VERSION ""

NS_ :

BS_:

BU_:

BO_ 2566848608 osm_msg5: 8 Vector__XXX
 SG_ tp_alarm : 0|1@1+ (1,0) [0|1] "" Vector__XXX

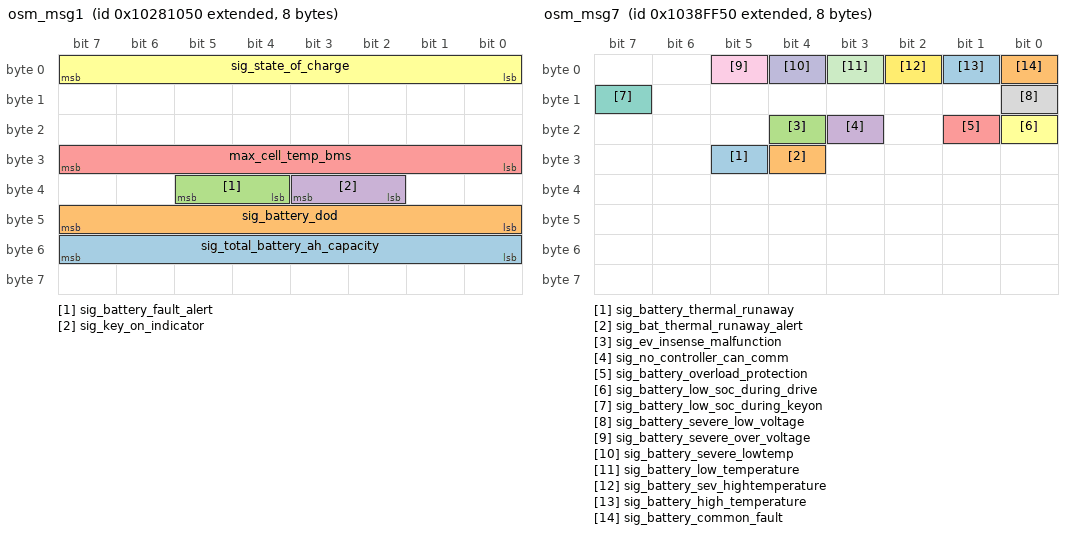
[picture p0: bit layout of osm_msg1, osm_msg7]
BO_ 2418544720 osm_msg1: 8 Vector__XXX
 SG_ sig_total_battery_ah_capacity : 48|8@1+ (1,0) [0|255] "" Vector__XXX
 SG_ sig_battery_dod : 40|8@1+ (1,0) [0|255] "" Vector__XXX
 SG_ sig_battery_fault_alert : 36|2@1+ (1,0) [0|3] "" Vector__XXX
 SG_ sig_key_on_indicator : 34|2@1+ (1,0) [0|3] "" Vector__XXX
 SG_ max_cell_temp_bms : 24|8@1- (1,0) [-128|127] "" Vector__XXX
 SG_ sig_state_of_charge : 0|8@1+ (1,0) [0|255] "" Vector__XXX

BO_ 2419654480 osm_msg7: 8 Vector__XXX
 SG_ sig_battery_thermal_runaway : 29|1@1+ (1,0) [0|1] "" Vector__XXX
 SG_ sig_bat_thermal_runaway_alert : 28|1@1+ (1,0) [0|1] "" Vector__XXX
 SG_ sig_ev_insense_malfunction : 20|1@1+ (1,0) [0|1] "" Vector__XXX
 SG_ sig_no_controller_can_comm : 19|1@1+ (1,0) [0|1] "" Vector__XXX
 SG_ sig_battery_overload_protection : 17|1@1+ (1,0) [0|1] "" Vector__XXX
 SG_ sig_battery_low_soc_during_drive : 16|1@1+ (1,0) [0|1] "" Vector__XXX
 SG_ sig_battery_low_soc_during_keyon : 15|1@1+ (1,0) [0|1] "" Vector__XXX
 SG_ sig_battery_severe_low_voltage : 8|1@1+ (1,0) [0|1] "" Vector__XXX
 SG_ sig_battery_severe_over_voltage : 5|1@1+ (1,0) [0|1] "" Vector__XXX
 SG_ sig_battery_severe_lowtemp : 4|1@1+ (1,0) [0|1] "" Vector__XXX
 SG_ sig_battery_low_temperature : 3|1@1+ (1,0) [0|1] "" Vector__XXX
 SG_ sig_battery_sev_hightemperature : 2|1@1+ (1,0) [0|1] "" Vector__XXX
 SG_ sig_battery_high_temperature : 1|1@1+ (1,0) [0|1] "" Vector__XXX
 SG_ sig_battery_common_fault : 0|1@1+ (1,0) [0|1] "" Vector__XXX

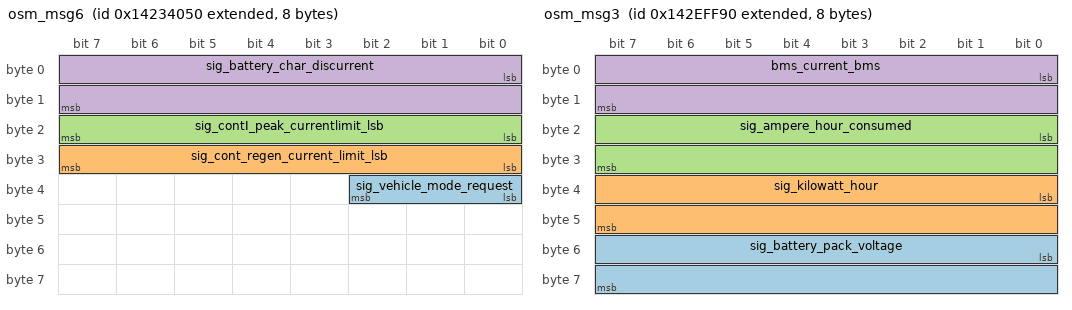
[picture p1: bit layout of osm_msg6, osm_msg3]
BO_ 2485338192 osm_msg6: 8 Vector__XXX
 SG_ sig_vehicle_mode_request : 32|3@1+ (1,0) [0|7] "" Vector__XXX
 SG_ sig_cont_regen_current_limit_lsb : 24|8@1+ (1,0) [0|255] "" Vector__XXX
 SG_ sig_contI_peak_currentlimit_lsb : 16|8@1+ (1,0) [0|255] "" Vector__XXX
 SG_ sig_battery_char_discurrent : 0|16@1- (0.1,0.0) [-3276.8|3276.7000000000003] "" Vector__XXX

BO_ 2485403728 osm_msg8: 8 Vector__XXX
 SG_ max_cell_voltage_bms : 32|16@1+ (0.001,0.0) [0.0|65.535] "" Vector__XXX
 SG_ min_cell_voltage_bms : 0|16@1+ (0.001,0.0) [0.0|65.535] "" Vector__XXX

BO_ 2486108048 osm_msg3: 8 Vector__XXX
 SG_ sig_battery_pack_voltage : 48|16@1+ (0.01,0.0) [0.0|655.35] "" Vector__XXX
 SG_ sig_kilowatt_hour : 32|16@1- (0.01,0.0) [-327.68|327.67] "" Vector__XXX
 SG_ sig_ampere_hour_consumed : 16|16@1- (0.01,0.0) [-327.68|327.67] "" Vector__XXX
 SG_ bms_current_bms : 0|16@1- (0.1,0.0) [-3276.8|3276.7000000000003] "" Vector__XXX

BO_ 2566849376 osm_msg4: 8 Vector__XXX
 SG_ sig_battery_state : 56|8@1+ (1,0) [0|255] "" Vector__XXX
 SG_ sig_battery_charging_cycles : 40|16@1+ (1,0) [0|65535] "" Vector__XXX

BO_ 2418499664 osm_msg9: 8 Vector__XXX
 SG_ sig_bms_software_ver : 32|32@1+ (1,0) [0|4294967295] "" Vector__XXX
 SG_ sig_bms_hardware_ver : 0|32@1+ (1,0) [0|4294967295] "" Vector__XXX

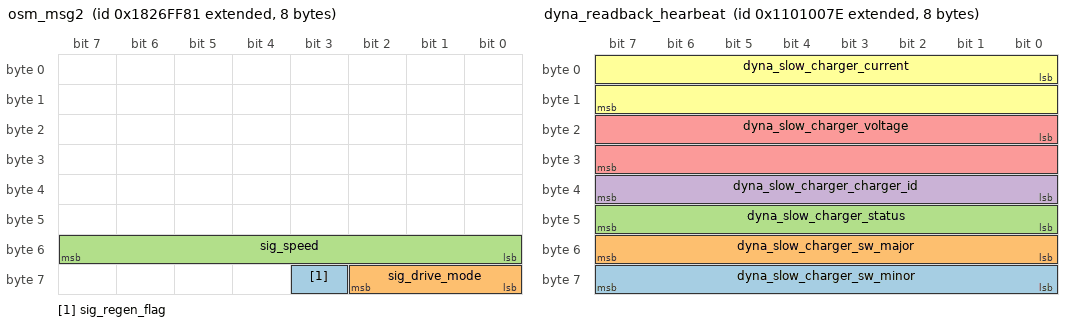
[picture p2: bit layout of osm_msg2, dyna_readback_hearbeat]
BO_ 2552692609 osm_msg2: 8 Vector__XXX
 SG_ sig_regen_flag : 59|1@1+ (1,0) [0|1] "" Vector__XXX
 SG_ sig_drive_mode : 56|3@1+ (1,0) [0|7] "" Vector__XXX
 SG_ sig_speed : 48|8@1+ (1,0) [0|255] "" Vector__XXX

BO_ 2432761982 dyna_readback_hearbeat: 8 Vector__XXX
 SG_ dyna_slow_charger_sw_minor : 56|8@1+ (1,0) [0|255] "" Vector__XXX
 SG_ dyna_slow_charger_sw_major : 48|8@1+ (1,0) [0|255] "" Vector__XXX
 SG_ dyna_slow_charger_status : 40|8@1+ (1,0) [0|255] "" Vector__XXX
 SG_ dyna_slow_charger_charger_id : 32|8@1+ (1,0) [0|255] "" Vector__XXX
 SG_ dyna_slow_charger_voltage : 16|16@1+ (1,0) [0|65535] "" Vector__XXX
 SG_ dyna_slow_charger_current : 0|16@1+ (1,0) [0|65535] "" Vector__XXX

BO_ 2424406782 stecom_charger_mode_set: 8 Vector__XXX
 SG_ dyna_out_accept_2 : 8|8@1+ (1,0) [0|255] "" Vector__XXX
 SG_ dyna_out_accept : 0|8@1+ (1,0) [0|255] "" Vector__XXX

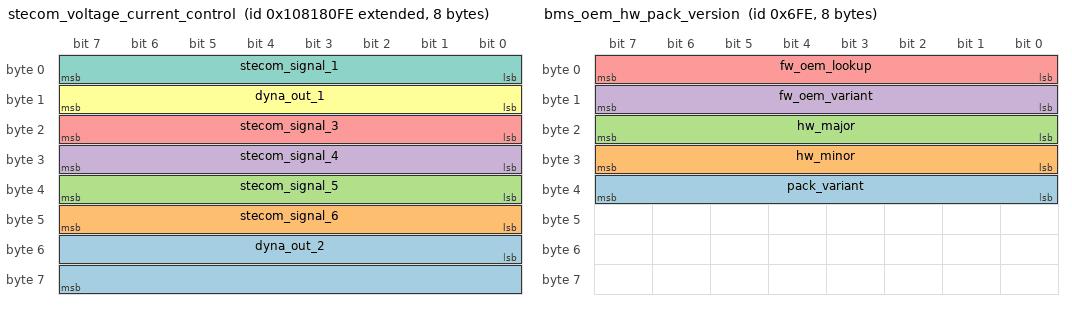
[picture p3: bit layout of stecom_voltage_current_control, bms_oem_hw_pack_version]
BO_ 2424406270 stecom_voltage_current_control: 8 Vector__XXX
 SG_ dyna_out_2 : 48|16@1+ (1,0) [0|65535] "" Vector__XXX
 SG_ stecom_signal_6 : 40|8@1+ (1,0) [0|255] "" Vector__XXX
 SG_ stecom_signal_5 : 32|8@1+ (1,0) [0|255] "" Vector__XXX
 SG_ stecom_signal_4 : 24|8@1+ (1,0) [0|255] "" Vector__XXX
 SG_ stecom_signal_3 : 16|8@1+ (1,0) [0|255] "" Vector__XXX
 SG_ dyna_out_1 : 8|8@1+ (1,0) [0|255] "" Vector__XXX
 SG_ stecom_signal_1 : 0|8@1+ (1,0) [0|255] "" Vector__XXX

BO_ 1790 bms_oem_hw_pack_version: 8 Vector__XXX
 SG_ pack_variant : 32|8@1+ (1,0) [0|255] "" Vector__XXX
 SG_ hw_minor : 24|8@1+ (1,0) [0|255] "" Vector__XXX
 SG_ hw_major : 16|8@1+ (1,0) [0|255] "" Vector__XXX
 SG_ fw_oem_variant : 8|8@1+ (1,0) [0|255] "" Vector__XXX
 SG_ fw_oem_lookup : 0|8@1+ (1,0) [0|255] "" Vector__XXX

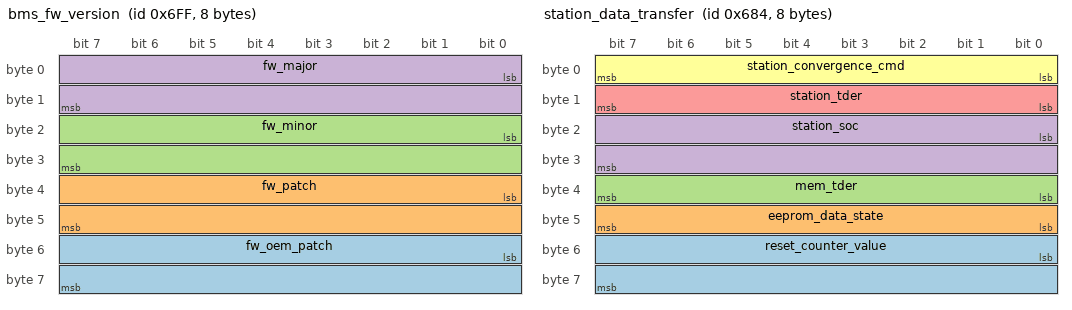
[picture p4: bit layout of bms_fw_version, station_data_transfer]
BO_ 1791 bms_fw_version: 8 Vector__XXX
 SG_ fw_oem_patch : 48|16@1+ (1,0) [0|65535] "" Vector__XXX
 SG_ fw_patch : 32|16@1+ (1,0) [0|65535] "" Vector__XXX
 SG_ fw_minor : 16|16@1+ (1,0) [0|65535] "" Vector__XXX
 SG_ fw_major : 0|16@1+ (1,0) [0|65535] "" Vector__XXX

BO_ 1668 station_data_transfer: 8 Vector__XXX
 SG_ reset_counter_value : 48|16@1+ (1,0) [0|65535] "" Vector__XXX
 SG_ eeprom_data_state : 40|8@1+ (1,0) [0|255] "" Vector__XXX
 SG_ mem_tder : 32|8@1+ (1,0) [0|255] "" Vector__XXX
 SG_ station_soc : 16|16@1+ (1,0.1) [0.1|65535.1] "" Vector__XXX
 SG_ station_tder : 8|8@1+ (1,0) [0|255] "" Vector__XXX
 SG_ station_convergence_cmd : 0|8@1+ (1,0) [0|255] "" Vector__XXX

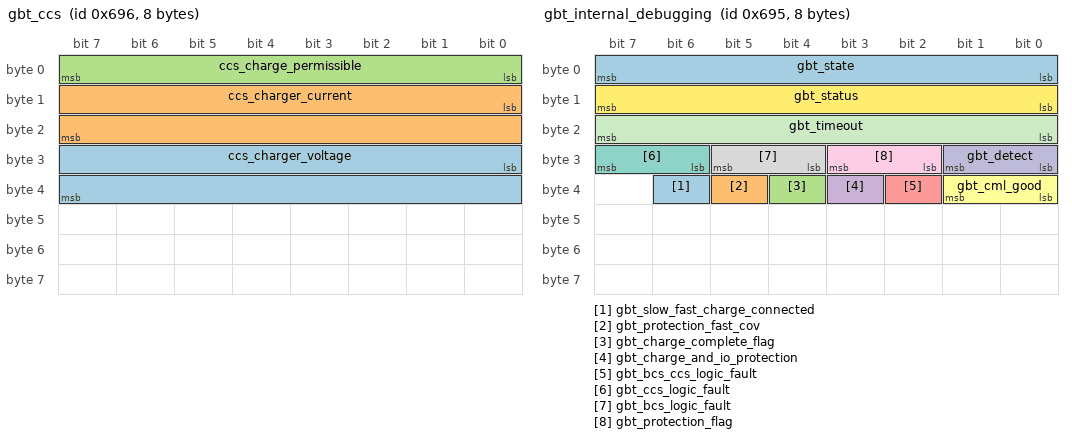
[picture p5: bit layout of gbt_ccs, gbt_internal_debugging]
BO_ 1686 gbt_ccs: 8 Vector__XXX
 SG_ ccs_charger_voltage : 24|16@1+ (0.1,0.0) [0.0|6553.5] "" Vector__XXX
 SG_ ccs_charger_current : 8|16@1- (0.1,-400.0) [-3676.8|2876.7000000000003] "" Vector__XXX
 SG_ ccs_charge_permissible : 0|8@1+ (1,0) [0|255] "" Vector__XXX

BO_ 1681 gbt_bst_cst: 8 Vector__XXX
 SG_ cst_byte3 : 56|8@1+ (1,0) [0|255] "" Vector__XXX
 SG_ cst_byte2 : 48|8@1+ (1,0) [0|255] "" Vector__XXX
 SG_ csr_byte1 : 40|8@1+ (1,0) [0|255] "" Vector__XXX
 SG_ cst_byte0 : 32|8@1+ (1,0) [0|255] "" Vector__XXX
 SG_ bst_voltage_error : 26|2@1+ (1,0) [0|3] "" Vector__XXX
 SG_ bst_current_error : 24|2@1+ (1,0) [0|3] "" Vector__XXX
 SG_ bst_other_fault : 22|2@1+ (1,0) [0|3] "" Vector__XXX
 SG_ bst_voltage_detection_fault : 20|2@1+ (1,0) [0|3] "" Vector__XXX
 SG_ bst_hv_relay_fault : 18|2@1+ (1,0) [0|3] "" Vector__XXX
 SG_ bst_battery_ot_fault : 16|2@1+ (1,0) [0|3] "" Vector__XXX
 SG_ bst_charging_connector_fault : 14|2@1+ (1,0) [0|3] "" Vector__XXX
 SG_ bst_bms_component_fault : 12|2@1+ (1,0) [0|3] "" Vector__XXX
 SG_ bst_output_connector_ot_fault : 10|2@1+ (1,0) [0|3] "" Vector__XXX
 SG_ bst_insulation_fault : 8|2@1+ (1,0) [0|3] "" Vector__XXX
 SG_ bst_cst_cause : 6|2@1+ (1,0) [0|3] "" Vector__XXX
 SG_ bst_max_cell_volt_cause : 4|2@1+ (1,0) [0|3] "" Vector__XXX
 SG_ bst_pack_voltage_cause : 2|2@1+ (1,0) [0|3] "" Vector__XXX
 SG_ bst_soc_cause : 0|2@1+ (1,0) [0|3] "" Vector__XXX

BO_ 1685 gbt_internal_debugging: 8 Vector__XXX
 SG_ gbt_slow_fast_charge_connected : 38|1@1+ (1,0) [0|1] "" Vector__XXX
 SG_ gbt_protection_fast_cov : 37|1@1+ (1,0) [0|1] "" Vector__XXX
 SG_ gbt_charge_complete_flag : 36|1@1+ (1,0) [0|1] "" Vector__XXX
 SG_ gbt_charge_and_io_protection : 35|1@1+ (1,0) [0|1] "" Vector__XXX
 SG_ gbt_bcs_ccs_logic_fault : 34|1@1+ (1,0) [0|1] "" Vector__XXX
 SG_ gbt_cml_good : 32|2@1+ (1,0) [0|3] "" Vector__XXX
 SG_ gbt_ccs_logic_fault : 30|2@1+ (1,0) [0|3] "" Vector__XXX
 SG_ gbt_bcs_logic_fault : 28|2@1+ (1,0) [0|3] "" Vector__XXX
 SG_ gbt_protection_flag : 26|2@1+ (1,0) [0|3] "" Vector__XXX
 SG_ gbt_detect : 24|2@1+ (1,0) [0|3] "" Vector__XXX
 SG_ gbt_timeout : 16|8@1+ (1,0) [0|255] "" Vector__XXX
 SG_ gbt_status : 8|8@1+ (1,0) [0|255] "" Vector__XXX
 SG_ gbt_state : 0|8@1+ (1,0) [0|255] "" Vector__XXX

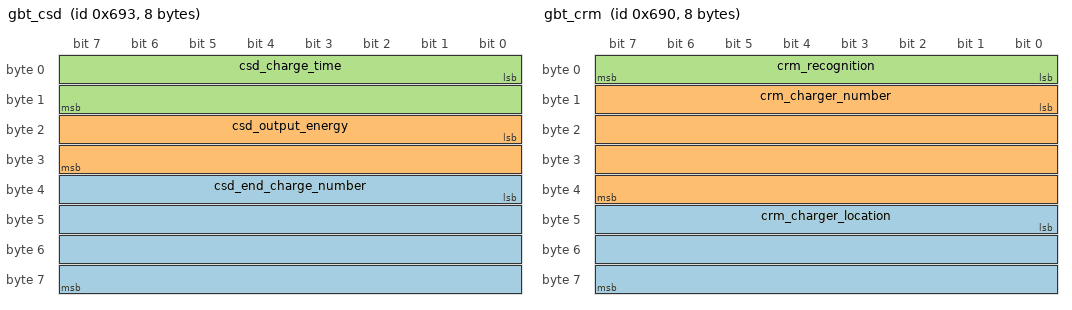
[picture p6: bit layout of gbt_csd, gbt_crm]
BO_ 1683 gbt_csd: 8 Vector__XXX
 SG_ csd_end_charge_number : 32|32@1+ (1,0) [0|4294967295] "" Vector__XXX
 SG_ csd_output_energy : 16|16@1+ (0.1,0.0) [0.0|6553.5] "" Vector__XXX
 SG_ csd_charge_time : 0|16@1+ (1,0) [0|65535] "" Vector__XXX

BO_ 1680 gbt_crm: 8 Vector__XXX
 SG_ crm_charger_location : 40|24@1+ (1,0) [0|16777215] "" Vector__XXX
 SG_ crm_charger_number : 8|32@1+ (1,0) [0|4294967295] "" Vector__XXX
 SG_ crm_recognition : 0|8@1+ (1,0) [0|255] "" Vector__XXX

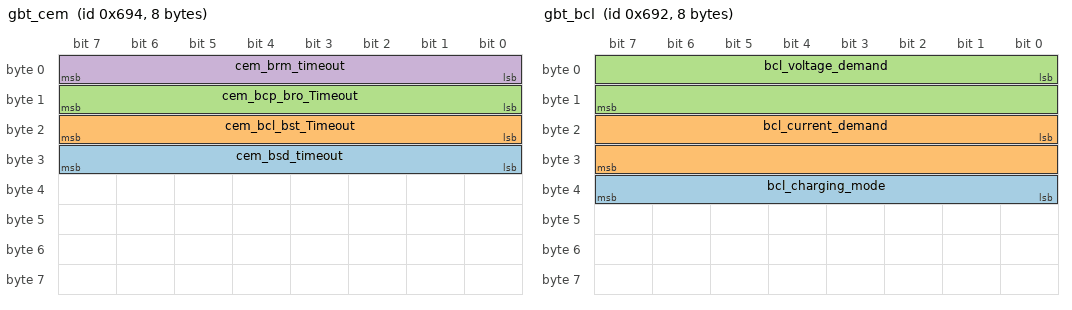
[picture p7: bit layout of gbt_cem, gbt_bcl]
BO_ 1684 gbt_cem: 8 Vector__XXX
 SG_ cem_bsd_timeout : 24|8@1+ (1,0) [0|255] "" Vector__XXX
 SG_ cem_bcl_bst_Timeout : 16|8@1+ (1,0) [0|255] "" Vector__XXX
 SG_ cem_bcp_bro_Timeout : 8|8@1+ (1,0) [0|255] "" Vector__XXX
 SG_ cem_brm_timeout : 0|8@1+ (1,0) [0|255] "" Vector__XXX

BO_ 1682 gbt_bcl: 8 Vector__XXX
 SG_ bcl_charging_mode : 32|8@1+ (1,0) [0|255] "" Vector__XXX
 SG_ bcl_current_demand : 16|16@1+ (0.1,-40.0) [-40.0|6513.5] "" Vector__XXX
 SG_ bcl_voltage_demand : 0|16@1+ (0.1,0.0) [0.0|6553.5] "" Vector__XXX

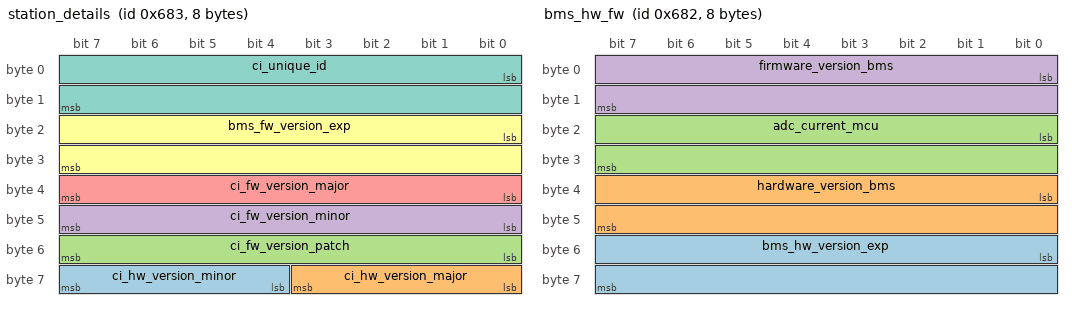
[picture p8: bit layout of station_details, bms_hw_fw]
BO_ 1667 station_details: 8 Vector__XXX
 SG_ ci_hw_version_minor : 60|4@1+ (1,0) [0|15] "" Vector__XXX
 SG_ ci_hw_version_major : 56|4@1+ (1,0) [0|15] "" Vector__XXX
 SG_ ci_fw_version_patch : 48|8@1+ (1,0) [0|255] "" Vector__XXX
 SG_ ci_fw_version_minor : 40|8@1+ (1,0) [0|255] "" Vector__XXX
 SG_ ci_fw_version_major : 32|8@1+ (1,0) [0|255] "" Vector__XXX
 SG_ bms_fw_version_exp : 16|16@1+ (1,0) [0|65535] "" Vector__XXX
 SG_ ci_unique_id : 0|16@1+ (1,0) [0|65535] "" Vector__XXX

BO_ 1666 bms_hw_fw: 8 Vector__XXX
 SG_ bms_hw_version_exp : 48|16@1+ (1,0) [0|65535] "" Vector__XXX
 SG_ hardware_version_bms : 32|16@1+ (1,0) [0|65535] "" Vector__XXX
 SG_ adc_current_mcu : 16|16@1+ (1,0) [0|65535] "" Vector__XXX
 SG_ firmware_version_bms : 0|16@1+ (1,0) [0|65535] "" Vector__XXX

BO_ 1665 bms_unique_Key: 8 Vector__XXX
 SG_ bms_unique_key : 0|64@1+ (1,0) [0|18446744073709551615] "" Vector__XXX

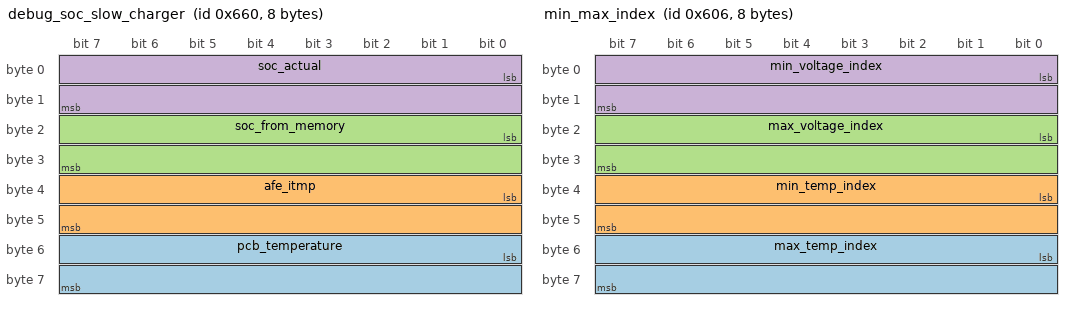
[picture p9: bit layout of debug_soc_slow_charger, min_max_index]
BO_ 1632 debug_soc_slow_charger: 8 Vector__XXX
 SG_ pcb_temperature : 48|16@1+ (0.01,-100.0) [-100.0|555.35] "" Vector__XXX
 SG_ afe_itmp : 32|16@1+ (0.01,-100.0) [-100.0|555.35] "" Vector__XXX
 SG_ soc_from_memory : 16|16@1+ (1,0) [0|65535] "" Vector__XXX
 SG_ soc_actual : 0|16@1+ (0.01,0.0) [0.0|655.35] "" Vector__XXX

BO_ 1542 min_max_index: 8 Vector__XXX
 SG_ max_temp_index : 48|16@1+ (1,0) [0|65535] "" Vector__XXX
 SG_ min_temp_index : 32|16@1+ (1,0) [0|65535] "" Vector__XXX
 SG_ max_voltage_index : 16|16@1+ (1,0) [0|65535] "" Vector__XXX
 SG_ min_voltage_index : 0|16@1+ (1,0) [0|65535] "" Vector__XXX

BO_ 1543 history_of_protections: 8 Vector__XXX
 SG_ reset_cause : 48|16@1+ (1,0) [0|65535] "" Vector__XXX
 SG_ characterization_cycle_count : 32|16@1+ (0.1,0.0) [0.0|6553.5] "" Vector__XXX
 SG_ ib1_bms_hist : 20|1@1+ (1,0) [0|1] "" Vector__XXX
 SG_ ccov_bms_hist : 19|1@1+ (1,0) [0|1] "" Vector__XXX
 SG_ sc_coc1_bms_hist : 18|1@1+ (1,0) [0|1] "" Vector__XXX
 SG_ ccuv_bms_hist : 17|1@1+ (1,0) [0|1] "" Vector__XXX
 SG_ icp_hist : 16|1@1+ (1,0) [0|1] "" Vector__XXX
 SG_ sc_coc_bms_hist : 15|1@1+ (1,0) [0|1] "" Vector__XXX
 SG_ roc_bms_hist : 14|1@1+ (1,0) [0|1] "" Vector__XXX
 SG_ scf_bms_hist : 13|1@1+ (1,0) [0|1] "" Vector__XXX
 SG_ tso_bms_hist : 12|1@1+ (1,0) [0|1] "" Vector__XXX
 SG_ ib_bms_hist : 11|1@1+ (1,0) [0|1] "" Vector__XXX
 SG_ cso_bms_hist : 10|1@1+ (1,0) [0|1] "" Vector__XXX
 SG_ dut_bms_hist : 9|1@1+ (1,0) [0|1] "" Vector__XXX
 SG_ cut_bms_hist : 8|1@1+ (1,0) [0|1] "" Vector__XXX
 SG_ dot_bms_hist : 7|1@1+ (1,0) [0|1] "" Vector__XXX
 SG_ cot_bms_hist : 6|1@1+ (1,0) [0|1] "" Vector__XXX
 SG_ doc_bms_hist : 5|1@1+ (1,0) [0|1] "" Vector__XXX
 SG_ coc_bms_hist : 4|1@1+ (1,0) [0|1] "" Vector__XXX
 SG_ puv_bms_hist : 3|1@1+ (1,0) [0|1] "" Vector__XXX
 SG_ pov_bms_hist : 2|1@1+ (1,0) [0|1] "" Vector__XXX
 SG_ cuv_bms_hist : 1|1@1+ (1,0) [0|1] "" Vector__XXX
 SG_ cov_bms_hist : 0|1@1+ (1,0) [0|1] "" Vector__XXX

BO_ 1664 battery_unique_key: 8 Vector__XXX
 SG_ battery_unique_key : 0|64@1+ (1,0) [0|18446744073709551615] "" Vector__XXX

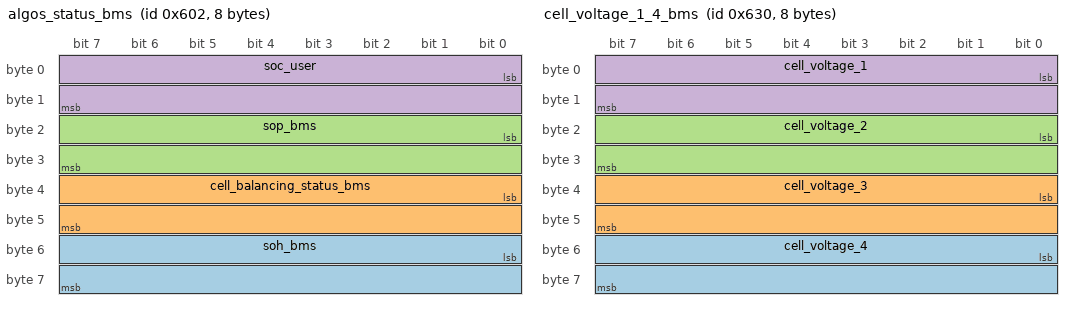
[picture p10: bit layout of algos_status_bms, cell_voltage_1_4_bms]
BO_ 1538 algos_status_bms: 8 Vector__XXX
 SG_ soh_bms : 48|16@1+ (0.01,0.0) [0.0|655.35] "" Vector__XXX
 SG_ cell_balancing_status_bms : 32|16@1+ (1,0) [0|65535] "" Vector__XXX
 SG_ sop_bms : 16|16@1+ (1,0) [0|65535] "" Vector__XXX
 SG_ soc_user : 0|16@1+ (0.01,0.0) [0.0|655.35] "" Vector__XXX

BO_ 1537 safety_status_bms: 8 Vector__XXX
 SG_ ib1_bms_flag : 52|1@1+ (1,0) [0|1] "" Vector__XXX
 SG_ ccov_flag_bms : 51|1@1+ (1,0) [0|1] "" Vector__XXX
 SG_ sc_coc1_flag_bms : 50|1@1+ (1,0) [0|1] "" Vector__XXX
 SG_ ccuv_flag_bms : 49|1@1+ (1,0) [0|1] "" Vector__XXX
 SG_ icp_flag : 48|1@1+ (1,0) [0|1] "" Vector__XXX
 SG_ sc_coc_flag_bms : 47|1@1+ (1,0) [0|1] "" Vector__XXX
 SG_ roc_flag_bms : 46|1@1+ (1,0) [0|1] "" Vector__XXX
 SG_ scf_flag_bms : 45|1@1+ (1,0) [0|1] "" Vector__XXX
 SG_ tso_flag_bms : 44|1@1+ (1,0) [0|1] "" Vector__XXX
 SG_ ib_bms_flag : 43|1@1+ (1,0) [0|1] "" Vector__XXX
 SG_ cso_flag_bms : 42|1@1+ (1,0) [0|1] "" Vector__XXX
 SG_ dut_flag_bms : 41|1@1+ (1,0) [0|1] "" Vector__XXX
 SG_ cut_flag_bms : 40|1@1+ (1,0) [0|1] "" Vector__XXX
 SG_ dot_flag_bms : 39|1@1+ (1,0) [0|1] "" Vector__XXX
 SG_ cot_flag_bms : 38|1@1+ (1,0) [0|1] "" Vector__XXX
 SG_ doc_flag_bms : 37|1@1+ (1,0) [0|1] "" Vector__XXX
 SG_ coc_flag_bms : 36|1@1+ (1,0) [0|1] "" Vector__XXX
 SG_ puv_flag_bms : 35|1@1+ (1,0) [0|1] "" Vector__XXX
 SG_ pov_flag_bms : 34|1@1+ (1,0) [0|1] "" Vector__XXX
 SG_ cuv_flag_bms : 33|1@1+ (1,0) [0|1] "" Vector__XXX
 SG_ cov_flag_bms : 32|1@1+ (1,0) [0|1] "" Vector__XXX
 SG_ ib1_bms : 20|1@1+ (1,0) [0|1] "" Vector__XXX
 SG_ ccov_bms : 19|1@1+ (1,0) [0|1] "" Vector__XXX
 SG_ sc_coc1_bms : 18|1@1+ (1,0) [0|1] "" Vector__XXX
 SG_ ccuv_bms : 17|1@1+ (1,0) [0|1] "" Vector__XXX
 SG_ icp_status : 16|1@1+ (1,0) [0|1] "" Vector__XXX
 SG_ sc_coc_bms : 15|1@1+ (1,0) [0|1] "" Vector__XXX
 SG_ roc_bms : 14|1@1+ (1,0) [0|1] "" Vector__XXX
 SG_ scf_bms : 13|1@1+ (1,0) [0|1] "" Vector__XXX
 SG_ tso_bms : 12|1@1+ (1,0) [0|1] "" Vector__XXX
 SG_ ib_bms : 11|1@1+ (1,0) [0|1] "" Vector__XXX
 SG_ cso_bms : 10|1@1+ (1,0) [0|1] "" Vector__XXX
 SG_ dut_bms : 9|1@1+ (1,0) [0|1] "" Vector__XXX
 SG_ cut_bms : 8|1@1+ (1,0) [0|1] "" Vector__XXX
 SG_ dot_bms : 7|1@1+ (1,0) [0|1] "" Vector__XXX
 SG_ cot_bms : 6|1@1+ (1,0) [0|1] "" Vector__XXX
 SG_ doc_bms : 5|1@1+ (1,0) [0|1] "" Vector__XXX
 SG_ coc_bms : 4|1@1+ (1,0) [0|1] "" Vector__XXX
 SG_ puv_bms : 3|1@1+ (1,0) [0|1] "" Vector__XXX
 SG_ pov_bms : 2|1@1+ (1,0) [0|1] "" Vector__XXX
 SG_ cuv_bms : 1|1@1+ (1,0) [0|1] "" Vector__XXX
 SG_ cov_bms : 0|1@1+ (1,0) [0|1] "" Vector__XXX

BO_ 1584 cell_voltage_1_4_bms: 8 Vector__XXX
 SG_ cell_voltage_4 : 48|16@1+ (0.0001,0.0) [0.0|6.5535000000000005] "" Vector__XXX
 SG_ cell_voltage_3 : 32|16@1+ (0.0001,0.0) [0.0|6.5535000000000005] "" Vector__XXX
 SG_ cell_voltage_2 : 16|16@1+ (0.0001,0.0) [0.0|6.5535000000000005] "" Vector__XXX
 SG_ cell_voltage_1 : 0|16@1+ (0.0001,0.0) [0.0|6.5535000000000005] "" Vector__XXX

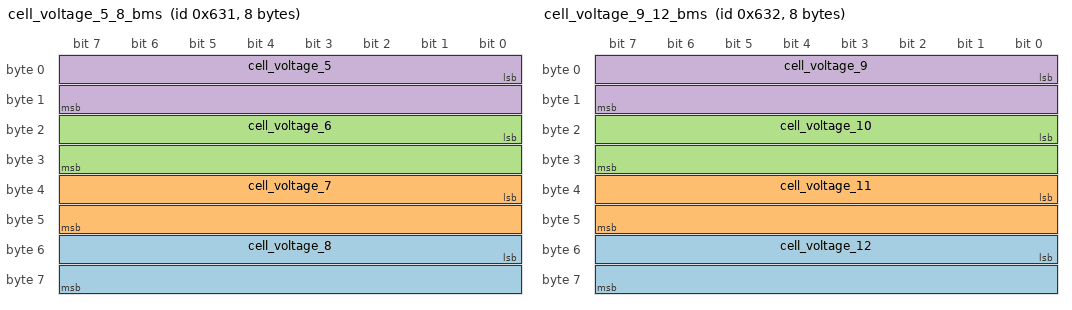
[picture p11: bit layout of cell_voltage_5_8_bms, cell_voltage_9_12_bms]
BO_ 1585 cell_voltage_5_8_bms: 8 Vector__XXX
 SG_ cell_voltage_8 : 48|16@1+ (0.0001,0.0) [0.0|6.5535000000000005] "" Vector__XXX
 SG_ cell_voltage_7 : 32|16@1+ (0.0001,0.0) [0.0|6.5535000000000005] "" Vector__XXX
 SG_ cell_voltage_6 : 16|16@1+ (0.0001,0.0) [0.0|6.5535000000000005] "" Vector__XXX
 SG_ cell_voltage_5 : 0|16@1+ (0.0001,0.0) [0.0|6.5535000000000005] "" Vector__XXX

BO_ 1586 cell_voltage_9_12_bms: 8 Vector__XXX
 SG_ cell_voltage_12 : 48|16@1+ (0.0001,0.0) [0.0|6.5535000000000005] "" Vector__XXX
 SG_ cell_voltage_11 : 32|16@1+ (0.0001,0.0) [0.0|6.5535000000000005] "" Vector__XXX
 SG_ cell_voltage_10 : 16|16@1+ (0.0001,0.0) [0.0|6.5535000000000005] "" Vector__XXX
 SG_ cell_voltage_9 : 0|16@1+ (0.0001,0.0) [0.0|6.5535000000000005] "" Vector__XXX

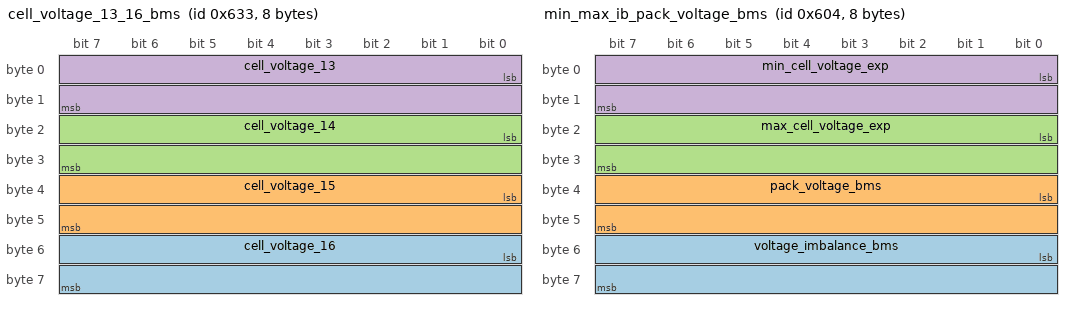
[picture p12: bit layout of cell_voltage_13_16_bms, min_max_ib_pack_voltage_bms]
BO_ 1587 cell_voltage_13_16_bms: 8 Vector__XXX
 SG_ cell_voltage_16 : 48|16@1+ (0.0001,0.0) [0.0|6.5535000000000005] "" Vector__XXX
 SG_ cell_voltage_15 : 32|16@1+ (0.0001,0.0) [0.0|6.5535000000000005] "" Vector__XXX
 SG_ cell_voltage_14 : 16|16@1+ (0.0001,0.0) [0.0|6.5535000000000005] "" Vector__XXX
 SG_ cell_voltage_13 : 0|16@1+ (0.0001,0.0) [0.0|6.5535000000000005] "" Vector__XXX

BO_ 1540 min_max_ib_pack_voltage_bms: 8 Vector__XXX
 SG_ voltage_imbalance_bms : 48|16@1+ (0.0001,0.0) [0.0|6.5535000000000005] "" Vector__XXX
 SG_ pack_voltage_bms : 32|16@1+ (0.01,0.0) [0.0|655.35] "" Vector__XXX
 SG_ max_cell_voltage_exp : 16|16@1+ (0.0001,0.0) [0.0|6.5535000000000005] "" Vector__XXX
 SG_ min_cell_voltage_exp : 0|16@1+ (0.0001,0.0) [0.0|6.5535000000000005] "" Vector__XXX

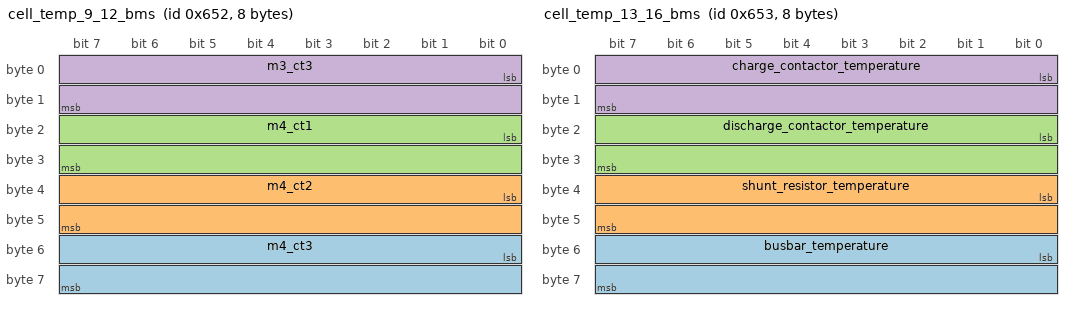
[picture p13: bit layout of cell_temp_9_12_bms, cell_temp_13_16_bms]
BO_ 1618 cell_temp_9_12_bms: 8 Vector__XXX
 SG_ m4_ct3 : 48|16@1+ (0.01,-100.0) [-100.0|555.35] "" Vector__XXX
 SG_ m4_ct2 : 32|16@1+ (0.01,-100.0) [-100.0|555.35] "" Vector__XXX
 SG_ m4_ct1 : 16|16@1+ (0.01,-100.0) [-100.0|555.35] "" Vector__XXX
 SG_ m3_ct3 : 0|16@1+ (0.01,-100.0) [-100.0|555.35] "" Vector__XXX

BO_ 1619 cell_temp_13_16_bms: 8 Vector__XXX
 SG_ busbar_temperature : 48|16@1+ (0.01,-100.0) [-100.0|555.35] "" Vector__XXX
 SG_ shunt_resistor_temperature : 32|16@1+ (0.01,-100.0) [-100.0|555.35] "" Vector__XXX
 SG_ discharge_contactor_temperature : 16|16@1+ (0.01,-100.0) [-100.0|555.35] "" Vector__XXX
 SG_ charge_contactor_temperature : 0|16@1+ (0.01,-100.0) [-100.0|555.35] "" Vector__XXX

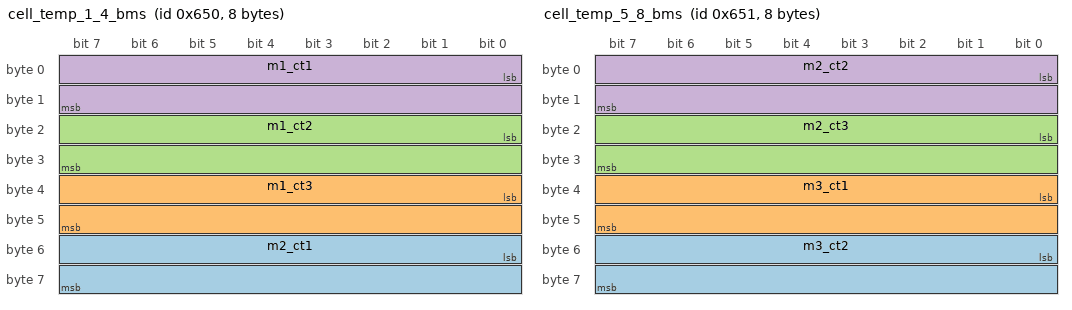
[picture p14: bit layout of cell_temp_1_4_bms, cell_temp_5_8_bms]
BO_ 1616 cell_temp_1_4_bms: 8 Vector__XXX
 SG_ m2_ct1 : 48|16@1+ (0.01,-100.0) [-100.0|555.35] "" Vector__XXX
 SG_ m1_ct3 : 32|16@1+ (0.01,-100.0) [-100.0|555.35] "" Vector__XXX
 SG_ m1_ct2 : 16|16@1+ (0.01,-100.0) [-100.0|555.35] "" Vector__XXX
 SG_ m1_ct1 : 0|16@1+ (0.01,-100.0) [-100.0|555.35] "" Vector__XXX

BO_ 1617 cell_temp_5_8_bms: 8 Vector__XXX
 SG_ m3_ct2 : 48|16@1+ (0.01,-100.0) [-100.0|555.35] "" Vector__XXX
 SG_ m3_ct1 : 32|16@1+ (0.01,-100.0) [-100.0|555.35] "" Vector__XXX
 SG_ m2_ct3 : 16|16@1+ (0.01,-100.0) [-100.0|555.35] "" Vector__XXX
 SG_ m2_ct2 : 0|16@1+ (0.01,-100.0) [-100.0|555.35] "" Vector__XXX

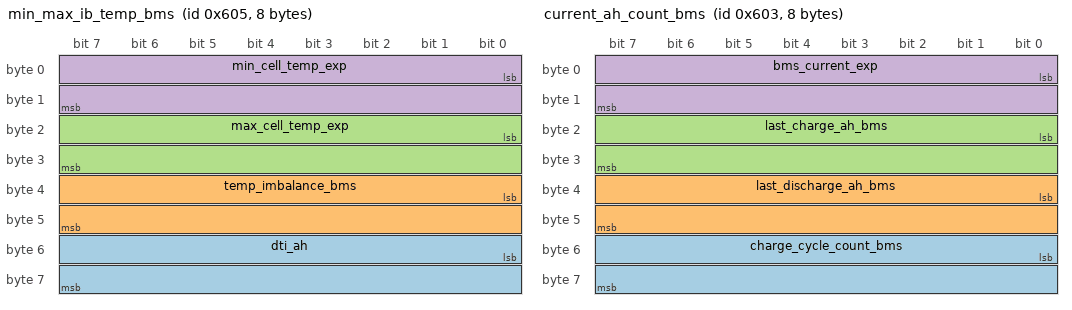
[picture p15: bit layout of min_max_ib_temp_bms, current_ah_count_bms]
BO_ 1541 min_max_ib_temp_bms: 8 Vector__XXX
 SG_ dti_ah : 48|16@1+ (0.1,0.0) [0.0|6553.5] "" Vector__XXX
 SG_ temp_imbalance_bms : 32|16@1+ (0.01,-100.0) [-100.0|555.35] "" Vector__XXX
 SG_ max_cell_temp_exp : 16|16@1+ (0.01,-100.0) [-100.0|555.35] "" Vector__XXX
 SG_ min_cell_temp_exp : 0|16@1+ (0.01,-100.0) [-100.0|555.35] "" Vector__XXX

BO_ 1539 current_ah_count_bms: 8 Vector__XXX
 SG_ charge_cycle_count_bms : 48|16@1+ (0.1,0.0) [0.0|6553.5] "" Vector__XXX
 SG_ last_discharge_ah_bms : 32|16@1+ (0.1,0.0) [0.0|6553.5] "" Vector__XXX
 SG_ last_charge_ah_bms : 16|16@1+ (0.1,0.0) [0.0|6553.5] "" Vector__XXX
 SG_ bms_current_exp : 0|16@1+ (0.1,-600.0) [-600.0|5953.5] "" Vector__XXX

BO_ 1536 sateflow_status_bms: 8 Vector__XXX
 SG_ gun_unlock_retry_count : 60|4@1+ (1,0) [0|15] "" Vector__XXX
 SG_ gun_lock_retry_count : 56|4@1+ (1,0) [0|15] "" Vector__XXX
 SG_ solenoid_feedback : 53|1@1+ (1,0) [0|1] "" Vector__XXX
 SG_ gun_lock_req : 52|1@1+ (1,0) [0|1] "" Vector__XXX
 SG_ gun_unlock_failed : 51|1@1+ (1,0) [0|1] "" Vector__XXX
 SG_ gun_unlock_status : 50|1@1+ (1,0) [0|1] "" Vector__XXX
 SG_ gun_lock_failed : 49|1@1+ (1,0) [0|1] "" Vector__XXX
 SG_ gun_lock_status : 48|1@1+ (1,0) [0|1] "" Vector__XXX
 SG_ cc_on_req : 39|1@1+ (1,0) [0|1] "" Vector__XXX
 SG_ motor_enable_out_bms : 38|1@1+ (1,0) [0|1] "" Vector__XXX
 SG_ discharge_contactor_out_bms : 37|1@1+ (1,0) [0|1] "" Vector__XXX
 SG_ discharge_precharge_out_bms : 36|1@1+ (1,0) [0|1] "" Vector__XXX
 SG_ charge_contactor_out_bms : 35|1@1+ (1,0) [0|1] "" Vector__XXX
 SG_ charge_precharge_out_bms : 34|1@1+ (1,0) [0|1] "" Vector__XXX
 SG_ proximity_pilot_in_bms : 33|1@1+ (1,0) [0|1] "" Vector__XXX
 SG_ key_in_bms : 32|1@1+ (1,0) [0|1] "" Vector__XXX
 SG_ shutdown_flag_3 : 26|1@1+ (1,0) [0|1] "" Vector__XXX
 SG_ shutdown_flag_2 : 25|1@1+ (1,0) [0|1] "" Vector__XXX
 SG_ shutdown_flag_1 : 24|1@1+ (1,0) [0|1] "" Vector__XXX
 SG_ battery_state_bms : 16|8@1+ (1,0) [0|255] "" Vector__XXX
 SG_ tp_warning : 13|1@1+ (1,0) [0|1] "" Vector__XXX
 SG_ dot_warning : 12|1@1+ (1,0) [0|1] "" Vector__XXX
 SG_ tp_alarm_exp : 11|1@1+ (1,0) [0|1] "" Vector__XXX
 SG_ charge_complete_status : 10|1@1+ (1,0) [0|1] "" Vector__XXX
 SG_ fast_charger_detected_bms : 9|1@1+ (1,0) [0|1] "" Vector__XXX
 SG_ slow_charger_detected_bms : 8|1@1+ (1,0) [0|1] "" Vector__XXX
 SG_ discharge_path_status_bms : 7|1@1+ (1,0) [0|1] "" Vector__XXX
 SG_ charge_path_status_bms : 6|1@1+ (1,0) [0|1] "" Vector__XXX
 SG_ discharge_pf_ok_bms : 5|1@1+ (1,0) [0|1] "" Vector__XXX
 SG_ charge_pf_ok_bms : 4|1@1+ (1,0) [0|1] "" Vector__XXX
 SG_ discharge_io_ok_bms : 3|1@1+ (1,0) [0|1] "" Vector__XXX
 SG_ charge_io_ok_bms : 2|1@1+ (1,0) [0|1] "" Vector__XXX
 SG_ discharge_protection_ok_bms : 1|1@1+ (1,0) [0|1] "" Vector__XXX
 SG_ charge_protection_ok_bms : 0|1@1+ (1,0) [0|1] "" Vector__XXX

BO_ 1669 odo_details: 8 Vector__XXX
 SG_ odo_low : 16|16@1+ (1,0) [0|65535] "" Vector__XXX
 SG_ odo_high : 0|16@1+ (1,0) [0|65535] "" Vector__XXX

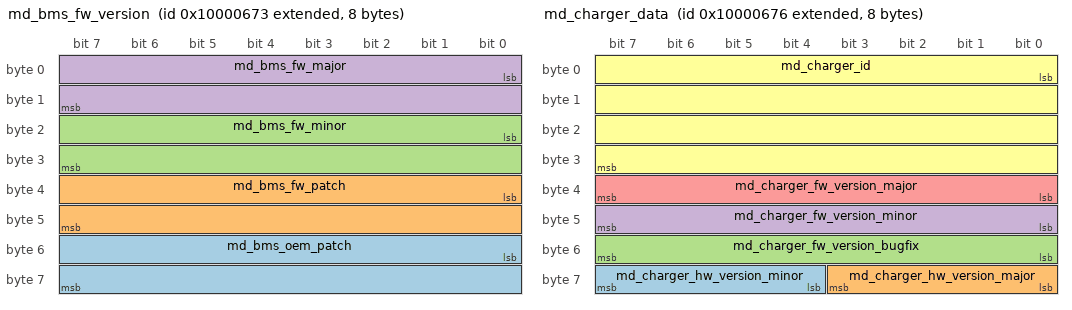
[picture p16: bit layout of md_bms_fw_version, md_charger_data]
BO_ 2415920755 md_bms_fw_version: 8 Vector__XXX
 SG_ md_bms_oem_patch : 48|16@1+ (1,0) [0|65535] "" Vector__XXX
 SG_ md_bms_fw_patch : 32|16@1+ (1,0) [0|65535] "" Vector__XXX
 SG_ md_bms_fw_minor : 16|16@1+ (1,0) [0|65535] "" Vector__XXX
 SG_ md_bms_fw_major : 0|16@1+ (1,0) [0|65535] "" Vector__XXX

BO_ 2415920758 md_charger_data: 8 Vector__XXX
 SG_ md_charger_hw_version_minor : 60|4@1+ (1,0) [0|15] "" Vector__XXX
 SG_ md_charger_hw_version_major : 56|4@1+ (1,0) [0|15] "" Vector__XXX
 SG_ md_charger_fw_version_bugfix : 48|8@1+ (1,0) [0|255] "" Vector__XXX
 SG_ md_charger_fw_version_minor : 40|8@1+ (1,0) [0|255] "" Vector__XXX
 SG_ md_charger_fw_version_major : 32|8@1+ (1,0) [0|255] "" Vector__XXX
 SG_ md_charger_id : 0|32@1+ (1,0) [0|4294967295] "" Vector__XXX

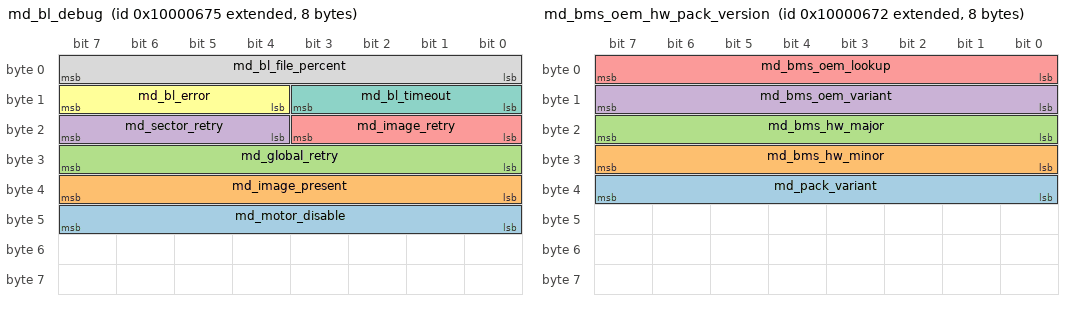
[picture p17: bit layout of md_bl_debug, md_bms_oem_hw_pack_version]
BO_ 2415920757 md_bl_debug: 8 Vector__XXX
 SG_ md_motor_disable : 40|8@1+ (1,0) [0|255] "" Vector__XXX
 SG_ md_image_present : 32|8@1+ (1,0) [0|255] "" Vector__XXX
 SG_ md_global_retry : 24|8@1+ (1,0) [0|255] "" Vector__XXX
 SG_ md_sector_retry : 20|4@1+ (1,0) [0|15] "" Vector__XXX
 SG_ md_image_retry : 16|4@1+ (1,0) [0|15] "" Vector__XXX
 SG_ md_bl_error : 12|4@1+ (1,0) [0|15] "" Vector__XXX
 SG_ md_bl_timeout : 8|4@1+ (1,0) [0|15] "" Vector__XXX
 SG_ md_bl_file_percent : 0|8@1+ (1,0) [0|255] "" Vector__XXX

BO_ 2415920756 md_soc_cycle_count: 8 Vector__XXX
 SG_ md_cycle_count : 8|16@1+ (1,0) [0|65535] "" Vector__XXX
 SG_ md_soc : 0|8@1+ (1,0) [0|255] "" Vector__XXX

BO_ 2415920754 md_bms_oem_hw_pack_version: 8 Vector__XXX
 SG_ md_pack_variant : 32|8@1+ (1,0) [0|255] "" Vector__XXX
 SG_ md_bms_hw_minor : 24|8@1+ (1,0) [0|255] "" Vector__XXX
 SG_ md_bms_hw_major : 16|8@1+ (1,0) [0|255] "" Vector__XXX
 SG_ md_bms_oem_variant : 8|8@1+ (1,0) [0|255] "" Vector__XXX
 SG_ md_bms_oem_lookup : 0|8@1+ (1,0) [0|255] "" Vector__XXX

BO_ 2415920753 md_battery_unique_key: 8 Vector__XXX
 SG_ md_battery_unique_key : 0|64@1+ (1,0) [0|18446744073709551615] "" Vector__XXX

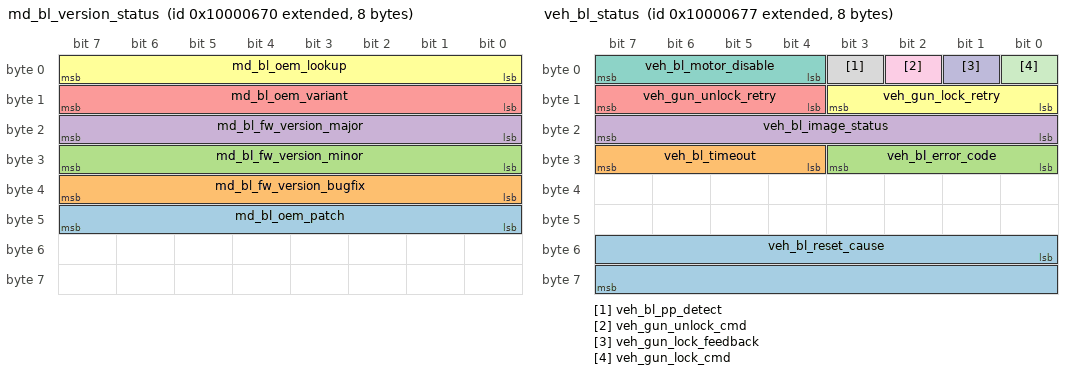
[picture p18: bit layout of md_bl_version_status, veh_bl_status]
BO_ 2415920752 md_bl_version_status: 8 Vector__XXX
 SG_ md_bl_oem_patch : 40|8@1+ (1,0) [0|255] "" Vector__XXX
 SG_ md_bl_fw_version_bugfix : 32|8@1+ (1,0) [0|255] "" Vector__XXX
 SG_ md_bl_fw_version_minor : 24|8@1+ (1,0) [0|255] "" Vector__XXX
 SG_ md_bl_fw_version_major : 16|8@1+ (1,0) [0|255] "" Vector__XXX
 SG_ md_bl_oem_variant : 8|8@1+ (1,0) [0|255] "" Vector__XXX
 SG_ md_bl_oem_lookup : 0|8@1+ (1,0) [0|255] "" Vector__XXX

BO_ 2415920759 veh_bl_status: 8 Vector__XXX
 SG_ veh_bl_reset_cause : 48|16@1+ (1,0) [0|65535] "" Vector__XXX
 SG_ veh_bl_timeout : 28|4@1+ (1,0) [0|15] "" Vector__XXX
 SG_ veh_bl_error_code : 24|4@1+ (1,0) [0|15] "" Vector__XXX
 SG_ veh_bl_image_status : 16|8@1+ (1,0) [0|255] "" Vector__XXX
 SG_ veh_gun_unlock_retry : 12|4@1+ (1,0) [0|15] "" Vector__XXX
 SG_ veh_gun_lock_retry : 8|4@1+ (1,0) [0|15] "" Vector__XXX
 SG_ veh_bl_motor_disable : 4|4@1+ (1,0) [0|15] "" Vector__XXX
 SG_ veh_bl_pp_detect : 3|1@1+ (1,0) [0|1] "" Vector__XXX
 SG_ veh_gun_unlock_cmd : 2|1@1+ (1,0) [0|1] "" Vector__XXX
 SG_ veh_gun_lock_feedback : 1|1@1+ (1,0) [0|1] "" Vector__XXX
 SG_ veh_gun_lock_cmd : 0|1@1+ (1,0) [0|1] "" Vector__XXX

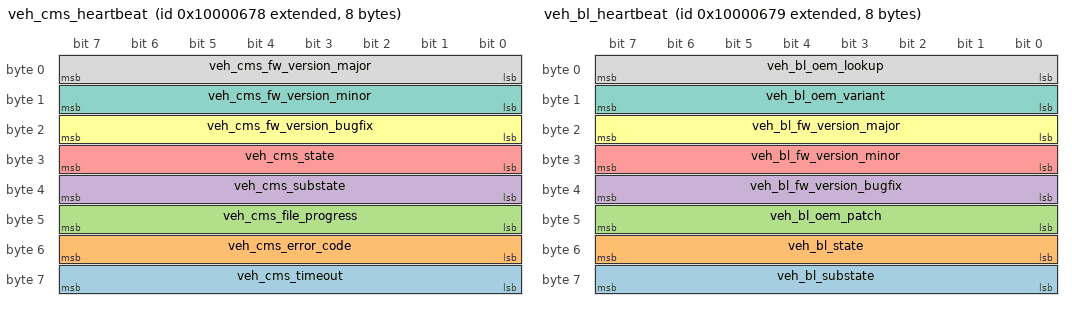
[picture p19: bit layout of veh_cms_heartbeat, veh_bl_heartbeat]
BO_ 2415920760 veh_cms_heartbeat: 8 Vector__XXX
 SG_ veh_cms_timeout : 56|8@1+ (1,0) [0|255] "" Vector__XXX
 SG_ veh_cms_error_code : 48|8@1+ (1,0) [0|255] "" Vector__XXX
 SG_ veh_cms_file_progress : 40|8@1+ (1,0) [0|255] "" Vector__XXX
 SG_ veh_cms_substate : 32|8@1+ (1,0) [0|255] "" Vector__XXX
 SG_ veh_cms_state : 24|8@1+ (1,0) [0|255] "" Vector__XXX
 SG_ veh_cms_fw_version_bugfix : 16|8@1+ (1,0) [0|255] "" Vector__XXX
 SG_ veh_cms_fw_version_minor : 8|8@1+ (1,0) [0|255] "" Vector__XXX
 SG_ veh_cms_fw_version_major : 0|8@1+ (1,0) [0|255] "" Vector__XXX

BO_ 2415920761 veh_bl_heartbeat: 8 Vector__XXX
 SG_ veh_bl_substate : 56|8@1+ (1,0) [0|255] "" Vector__XXX
 SG_ veh_bl_state : 48|8@1+ (1,0) [0|255] "" Vector__XXX
 SG_ veh_bl_oem_patch : 40|8@1+ (1,0) [0|255] "" Vector__XXX
 SG_ veh_bl_fw_version_bugfix : 32|8@1+ (1,0) [0|255] "" Vector__XXX
 SG_ veh_bl_fw_version_minor : 24|8@1+ (1,0) [0|255] "" Vector__XXX
 SG_ veh_bl_fw_version_major : 16|8@1+ (1,0) [0|255] "" Vector__XXX
 SG_ veh_bl_oem_variant : 8|8@1+ (1,0) [0|255] "" Vector__XXX
 SG_ veh_bl_oem_lookup : 0|8@1+ (1,0) [0|255] "" Vector__XXX
